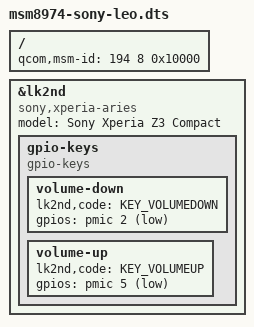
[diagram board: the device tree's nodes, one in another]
// SPDX-License-Identifier: GPL-2.0-only

/dts-v1/;

#include <skeleton32.dtsi>
#include <lk2nd.dtsi>

/ {
	qcom,msm-id = <194 8 0x10000>;
};

&lk2nd {
	model = "Sony Xperia Z3 Compact";
	compatible = "sony,xperia-aries";
	
	gpio-keys {
		compatible = "gpio-keys";
		
		volume-down {
			lk2nd,code = <KEY_VOLUMEDOWN>;
			gpios = <&pmic 2 (GPIO_ACTIVE_LOW | GPIO_PULL_UP)>;
		};
		
		volume-up {
			lk2nd,code = <KEY_VOLUMEUP>;
			gpios = <&pmic 5 (GPIO_ACTIVE_LOW | GPIO_PULL_UP)>;
		};
	};
};

#include "msm8974pro-ac-shinano_leo_display.dtsi"

